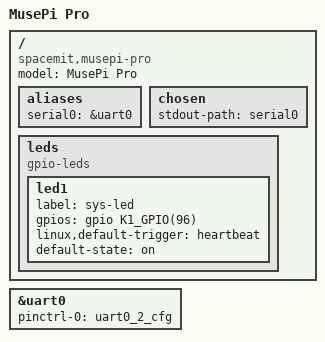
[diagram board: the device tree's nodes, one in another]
// SPDX-License-Identifier: (GPL-2.0 OR MIT)
/*
 * Copyright (C) 2024 Yangyu Chen <cyy@cyyself.name>
 * Copyright (C) 2025 Troy Mitchell <troy.mitchell@linux.spacemit.com>
 */

/dts-v1/;

#include "k1.dtsi"
#include "k1-pinctrl.dtsi"

/ {
	model = "MusePi Pro";
	compatible = "spacemit,musepi-pro", "spacemit,k1";

	aliases {
		serial0 = &uart0;
	};

	chosen {
		stdout-path = "serial0";
	};

	leds {
		compatible = "gpio-leds";

		led1 {
			label = "sys-led";
			gpios = <&gpio K1_GPIO(96) GPIO_ACTIVE_HIGH>;
			linux,default-trigger = "heartbeat";
			default-state = "on";
		};
	};
};

&uart0 {
	pinctrl-names = "default";
	pinctrl-0 = <&uart0_2_cfg>;
	status = "okay";
};
